# apollo3 register map
Vendor: Ambiq Micro; Series: Apollo; File version: 1.0
CPU: CM4 r1p0, little endian, MPU, FPU, 3 interrupt priority bits
Registers are 32-bit, read-write, reset 0x0 unless marked. A register's access mark holds for its fields unless they carry their own. Offsets are from the block's base; [hi:lo] are bit positions; 'fields as' and 'values as' point back to an identical list.

## MCUCTRL — MCU Miscellaneous Control Logic
Base 0x40020000
0x00 CHIPPN reset 0x4000000 — Chip Information Register
  [31:0] PARTNUM — BCD part number.
    0x6000000=APOLLO3 (Apollo3 part number is 0x06xxxxxx. value.); 0x3000000=APOLLO2 (Apollo2 part number is 0x03xxxxxx. value.); 0x1000000=APOLLO (Apollo part number is 0x01xxxxxx. value.); 0xFF000000=PN_M (Mask for the part number field. value.); 24=PN_S (Bit position for the part number field. value.); 0xF00000=FLASHSIZE_M (Mask for the FLASH_SIZE field. Values: 0: 16KB 1: 32KB 2: 64KB 3: 128KB 4: 256KB 5: 512KB 6: 1MB 7: 2MB value.); 20=FLASHSIZE_S (Bit position for the FLASH_SIZE field. value.); 0xF0000=SRAMSIZE_M (Mask for the SRAM_SIZE field. Values: 0: 16KB 1: 32KB 2: 64KB 3: 128KB 4: 256KB 5: 512KB 6: 1MB 7: 384KB value.); 16=SRAMSIZE_S (Bit position for the SRAM_SIZE field. value.); 0xFF00=REV_M (Mask for the revision field. Bits [15:12] are major rev, [11:8] are minor rev. Values: 0: Major Rev A, Minor Rev 0 1: Major Rev B, Minor Rev 1 value.); 8=REV_S (Bit position for the revision field. value.); 192=PKG_M (Mask for the package field. Values: 0: SIP 1: QFN 2: BGA 3: CSP value.); 6=PKG_S (Bit position for the package field. value.); 56=PINS_M (Mask for the pins field. Values: 0: 25 pins 1: 49 pins 2: 64 pins 3: 81 pins value.); 3=PINS_S (Bit position for the pins field. value.); 1=TEMP_S (Bit position for the temperature field. value.); 0=QUAL_S (Bit position for the qualified field. value.)
0x04 CHIPID0 — Unique Chip ID 0
  [31:0] CHIPID0 — Unique chip ID 0.
    0=APOLLO3 (Apollo3 CHIPID0. value.)
0x08 CHIPID1 — Unique Chip ID 1
  [31:0] CHIPID1 — Unique chip ID 1.
    0=APOLLO3 (Apollo3 CHIPID1. value.)
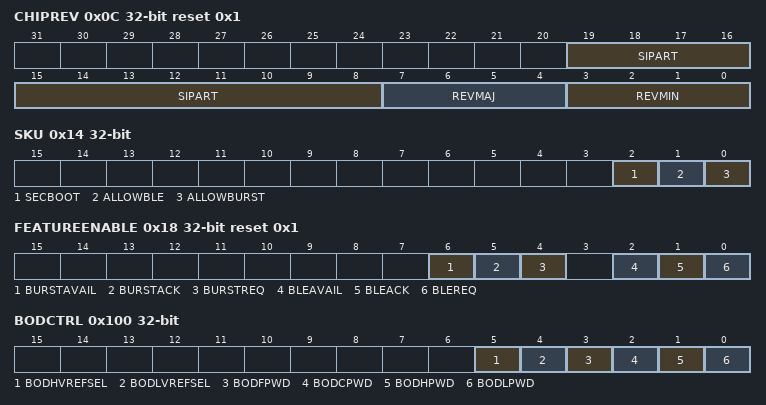
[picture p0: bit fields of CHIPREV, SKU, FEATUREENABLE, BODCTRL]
0x0C CHIPREV reset 0x1 — Chip Revision
  [19:8] SIPART — Silicon Part ID
  [7:4] REVMAJ — Major Revision ID.
    1=A (Apollo3 revision A value.)
  [3:0] REVMIN — Minor Revision ID.
    2=REV1 (Apollo3 minor rev 1. value.); 1=REV0 (Apollo3 minor rev 0. Minor revision value, succeeding minor revisions will increment from this value. value.)
0x10 VENDORID — Unique Vendor ID
  [31:0] VENDORID
    0x414D4251=AMBIQ (Ambiq Vendor ID value.)
0x14 SKU — Unique Chip SKU
  [2] SECBOOT — Secure boot feature allowed
  [1] ALLOWBLE — Allow BLE feature
  [0] ALLOWBURST — Allow Burst feature
0x18 FEATUREENABLE reset 0x1 — Feature Enable on Burst and BLE
  [6] BURSTAVAIL — Availability of Burst functionality
    1=AVAIL (Burst functionality available value.); 0=NOTAVAIL (Burst functionality not available value.)
  [5] BURSTACK — ACK for BURSTREQ
  [4] BURSTREQ — Controls the Burst functionality
    1=EN (Enable the Burst functionality value.); 0=DIS (Disable the Burst functionality value.)
  [2] BLEAVAIL — AVAILABILITY of the BLE functionality
    1=AVAIL (BLE functionality available value.); 0=NOTAVAIL (BLE functionality not available value.)
  [1] BLEACK — ACK for BLEREQ
  [0] BLEREQ — Controls the BLE functionality
    1=EN (Enable the BLE functionality value.); 0=DIS (Disable the BLE functionality value.)
0x20 DEBUGGER — Debugger Control
  [0] LOCKOUT — Lockout of debugger (SWD).
0x100 BODCTRL — BOD control Register
  [5] BODHVREFSEL — BODH External Reference Select. Note: the SWE mux select in PWRSEQ2SWE must be set for this to take effect.
  [4] BODLVREFSEL — BODL External Reference Select. Note: the SWE mux select in PWRSEQ2SWE must be set for this to take effect.
  [3] BODFPWD — BODF Power Down.
  [2] BODCPWD — BODC Power Down.
  [1] BODHPWD — BODH Power Down.
  [0] BODLPWD — BODL Power Down.
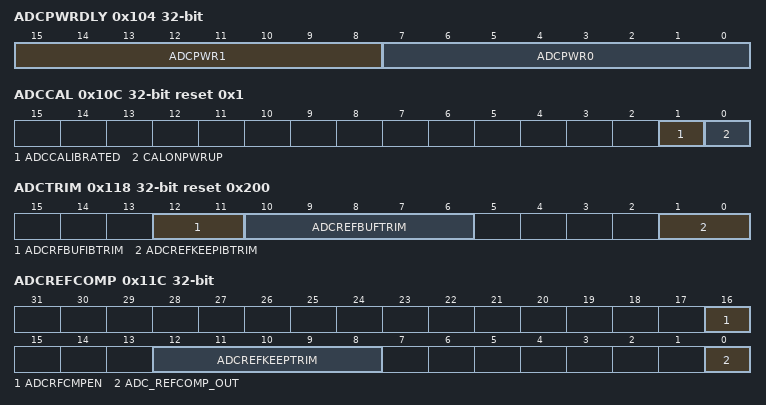
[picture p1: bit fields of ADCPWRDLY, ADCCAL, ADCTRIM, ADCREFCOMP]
0x104 ADCPWRDLY — ADC Power Up Delay Control
  [15:8] ADCPWR1 — ADC Reference Keeper enable delay in 16 ADC CLK increments for ADC_CLKSEL = 0x1, 8 ADC CLOCK increments for ADC_CLKSEL = 0x2.
  [7:0] ADCPWR0 — ADC Reference Buffer Power Enable delay in 64 ADC CLK increments for ADC_CLKSEL = 0x1, 32 ADC CLOCK increments for ADC_CLKSEL = 0x2.
0x10C ADCCAL reset 0x1 — ADC Calibration Control
  [1] ADCCALIBRATED — Status for ADC Calibration
    0=FALSE (ADC is not calibrated value.); 1=TRUE (ADC is calibrated value.)
  [0] CALONPWRUP — Run ADC Calibration on initial power up sequence
    0=DIS (Disable automatic calibration on initial power up value.); 1=EN (Enable automatic calibration on initial power up value.)
0x110 ADCBATTLOAD — ADC Battery Load Enable
  [0] BATTLOAD — Enable the ADC battery load resistor
    0=DIS (Battery load is disconnected value.); 1=EN (Battery load is enabled value.)
0x118 ADCTRIM reset 0x200 — ADC Trims
  [12:11] ADCRFBUFIBTRIM — ADC reference buffer input bias trim
  [10:6] ADCREFBUFTRIM — ADC Reference buffer trim
  [1:0] ADCREFKEEPIBTRIM — ADC Reference Ibias trim
0x11C ADCREFCOMP — ADC Referece Keeper and Comparator Control
  [16] ADCRFCMPEN — ADC Reference comparator power down
  [12:8] ADCREFKEEPTRIM — ADC Reference Keeper Trim
  [0] ADC_REFCOMP_OUT — Output of the ADC reference comparator
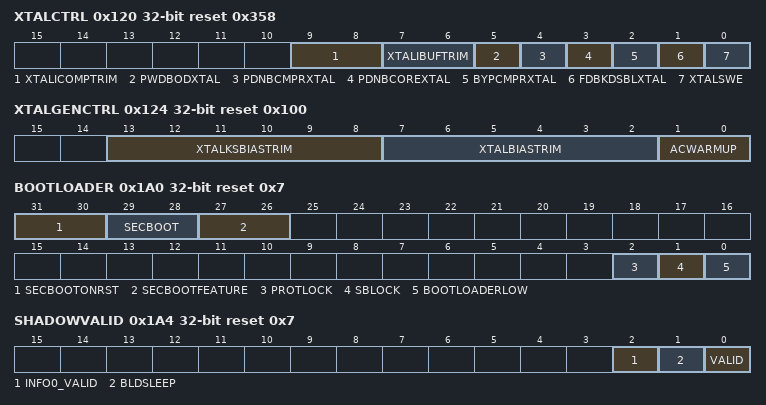
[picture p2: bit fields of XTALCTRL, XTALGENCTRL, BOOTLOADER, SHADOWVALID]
0x120 XTALCTRL reset 0x358 — XTAL Oscillator Control
  [9:8] XTALICOMPTRIM
  [7:6] XTALIBUFTRIM — XTAL IBUFF trim
  [5] PWDBODXTAL — XTAL Power down on brown out.
    0=PWRUPBOD (Power up xtal on BOD value.); 1=PWRDNBOD (Power down XTAL on BOD. value.)
  [4] PDNBCMPRXTAL — XTAL Oscillator Power Down Comparator.
    1=PWRUPCOMP (Power up XTAL oscillator comparator. value.); 0=PWRDNCOMP (Power down XTAL oscillator comparator. value.)
  [3] PDNBCOREXTAL — XTAL Oscillator Power Down Core.
    1=PWRUPCORE (Power up XTAL oscillator core. value.); 0=PWRDNCORE (Power down XTAL oscillator core. value.)
  [2] BYPCMPRXTAL — XTAL Oscillator Bypass Comparator.
    0=USECOMP (Use the XTAL oscillator comparator. value.); 1=BYPCOMP (Bypass the XTAL oscillator comparator. value.)
  [1] FDBKDSBLXTAL — XTAL Oscillator Disable Feedback.
    0=EN (Enable XTAL oscillator comparator. value.); 1=DIS (Disable XTAL oscillator comparator. value.)
  [0] XTALSWE — XTAL Software Override Enable.
    0=OVERRIDE_DIS (XTAL Software Override Disable. value.); 1=OVERRIDE_EN (XTAL Software Override Enable. value.)
0x124 XTALGENCTRL reset 0x100 — XTAL Oscillator General Control
  [13:8] XTALKSBIASTRIM — XTAL IBIAS Kick start trim. This trim value is used during the startup process to enable a faster lock.
  [7:2] XTALBIASTRIM
  [1:0] ACWARMUP — Auto-calibration delay control
    0=SEC1 (Warmup period of 1-2 seconds value.); 1=SEC2 (Warmup period of 2-4 seconds value.); 2=SEC4 (Warmup period of 4-8 seconds value.); 3=SEC8 (Warmup period of 8-16 seconds value.)
0x198 MISCCTRL — Miscellaneous control register.
  [5] BLE_RESETN — BLE reset signal.
0x1A0 BOOTLOADER reset 0x7 — Bootloader and secure boot functions
  [31:30] SECBOOTONRST — Indicates whether the secure boot on warm reset is enabled
    0=DISABLED (Secure boot disabled value.); 1=ENABLED (Secure boot enabled value.); 2=ERROR (Error in secure boot configuration value.)
  [29:28] SECBOOT — Indicates whether the secure boot on cold reset is enabled
    values as SECBOOTONRST
  [27:26] SECBOOTFEATURE — Indicates whether the secure boot feature is enabled.
    values as SECBOOTONRST
  [2] PROTLOCK — Flash protection lock. Always resets to 1, write 1 to clear. Enables writes to flash protection register set.
    1=LOCK (Enable the secure boot lock value.)
  [1] SBLOCK — Secure boot lock. Always resets to 1, write 1 to clear. Enables system visibility to bootloader until set.
    1=LOCK (Enable the secure boot lock value.)
  [0] BOOTLOADERLOW — Determines whether the bootloader code is visible at address 0x00000000 or not. Resets to 1, write 1 to clear.
    1=ADDR0 (Bootloader code at 0x00000000. value.)
0x1A4 SHADOWVALID reset 0x7 — Register to indicate whether the shadow registers have been successfully loaded from the Flash Information Space.
  [2] INFO0_VALID — Indicates whether info0 contains valid data
    1=VALID (Flash info0 (customer) space contains valid data. value.)
  [1] BLDSLEEP — Indicates whether the bootloader should sleep or deep sleep if no image loaded.
    1=DEEPSLEEP (Bootloader will go to deep sleep if no flash image loaded value.)
  [0] VALID — Indicates whether the shadow registers contain valid data from the Flash Information Space.
    1=VALID (Flash information space contains valid data. value.)
0x1B0 SCRATCH0 — Scratch register that is not reset by any reset
  [31:0] SCRATCH0 — Scratch register 0.
0x1B4 SCRATCH1 — Scratch register that is not reset by any reset
  [31:0] SCRATCH1 — Scratch register 1.
0x1C0 ICODEFAULTADDR — ICODE bus address which was present when a bus fault occurred.
  [31:0] ICODEFAULTADDR — The ICODE bus address observed when a Bus Fault occurred. Once an address is captured in this field, it is held until the corresponding Fault Observed bit is cleared in the FAULTSTATUS register.
0x1C4 DCODEFAULTADDR — DCODE bus address which was present when a bus fault occurred.
  [31:0] DCODEFAULTADDR — The DCODE bus address observed when a Bus Fault occurred. Once an address is captured in this field, it is held until the corresponding Fault Observed bit is cleared in the FAULTSTATUS register.
0x1C8 SYSFAULTADDR — System bus address which was present when a bus fault occurred.
  [31:0] SYSFAULTADDR — SYS bus address observed when a Bus Fault occurred. Once an address is captured in this field, it is held until the corresponding Fault Observed bit is cleared in the FAULTSTATUS register.
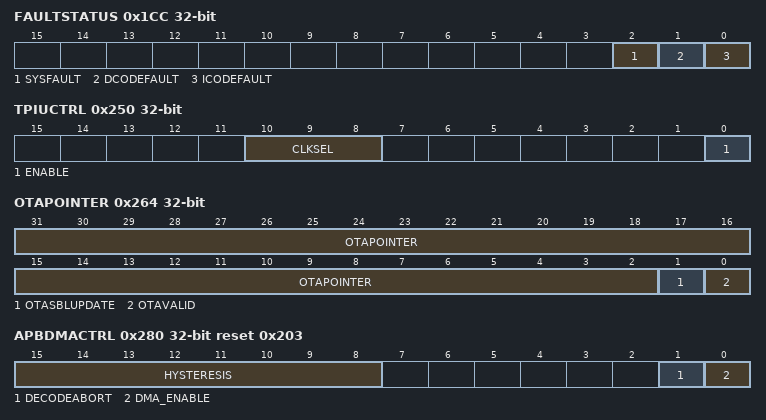
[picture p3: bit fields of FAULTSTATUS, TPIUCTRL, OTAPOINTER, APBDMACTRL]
0x1CC FAULTSTATUS — Reflects the status of the bus decoders' fault detection. Any write to this register will clear all of the status bits within the register.
  [2] SYSFAULT — SYS Bus Decoder Fault Detected bit. When set, a fault has been detected, and the SYSFAULTADDR register will contain the bus address which generated the fault.
    0=NOFAULT (No bus fault has been detected. value.); 1=FAULT (Bus fault detected. value.)
  [1] DCODEFAULT — DCODE Bus Decoder Fault Detected bit. When set, a fault has been detected, and the DCODEFAULTADDR register will contain the bus address which generated the fault.
    0=NOFAULT (No DCODE fault has been detected. value.); 1=FAULT (DCODE fault detected. value.)
  [0] ICODEFAULT — The ICODE Bus Decoder Fault Detected bit. When set, a fault has been detected, and the ICODEFAULTADDR register will contain the bus address which generated the fault.
    0=NOFAULT (No ICODE fault has been detected. value.); 1=FAULT (ICODE fault detected. value.)
0x1D0 FAULTCAPTUREEN — Enable the fault capture registers
  [0] FAULTCAPTUREEN — Fault Capture Enable field. When set, the Fault Capture monitors are enabled and addresses which generate a hard fault are captured into the FAULTADDR registers.
    0=DIS (Disable fault capture. value.); 1=EN (Enable fault capture. value.)
0x200 DBGR1 reset 0x12345678 — Read-only debug register 1
  [31:0] ONETO8 — Read-only register for communication validation
0x204 DBGR2 reset 0xC001C0DE — Read-only debug register 2
  [31:0] COOLCODE — Read-only register for communication validation
0x220 PMUENABLE reset 0x1 — Control bit to enable/disable the PMU
  [0] ENABLE — PMU Enable Control bit. When set, the MCU's PMU will place the MCU into the lowest power consuming Deep Sleep mode upon execution of a WFI instruction (dependent on the setting of the SLEEPDEEP bit in the ARM SCR register). When cleared, regardless of the requested sleep mode, the PMU will not enter the lowest power Deep Sleep mode, instead entering the Sleep mode.
    0=DIS (Disable MCU power management. value.); 1=EN (Enable MCU power management. value.)
0x250 TPIUCTRL — TPIU Control Register. Determines the clock enable and frequency for the M4's TPIU interface.
  [10:8] CLKSEL — This field selects the frequency of the ARM M4 TPIU port.
    0=LOWPWR (Low power state. value.); 1=HFRCDIV2 (Selects HFRC divided by 2 as the source TPIU clk value.); 2=HFRCDIV8 (Selects HFRC divided by 8 as the source TPIU clk value.); 3=HFRCDIV16 (Selects HFRC divided by 16 as the source TPIU clk value.); 4=HFRCDIV32 (Selects HFRC divided by 32 as the source TPIU clk value.)
  [0] ENABLE — TPIU Enable field. When set, the ARM M4 TPIU is enabled and data can be streamed out of the MCU's SWO port using the ARM ITM and TPIU modules.
    0=DIS (Disable the TPIU. value.); 1=EN (Enable the TPIU. value.)
0x264 OTAPOINTER — OTA (Over the Air) Update Pointer/Status. Reset only by POA
  [31:2] OTAPOINTER — Flash page pointer with updated OTA image
  [1] OTASBLUPDATE — Indicates that the sbl_init has been updated
  [0] OTAVALID — Indicates that an OTA update is valid
0x280 APBDMACTRL reset 0x203 — DMA Control Register. Determines misc settings for DMA operation
  [15:8] HYSTERESIS — This field determines how long the DMA will remain active during deep sleep before shutting down and returning the system to full deep sleep. Values are based on a 94KHz clock and are roughly 10us increments for a range of ~10us to 2.55ms
  [1] DECODEABORT — APB Decode Abort. When set, the APB bridge will issue a data abort (bus fault) on transactions to peripherals that are powered down. When set to 0, writes are quietly discarded and reads return 0.
    0=DISABLE (Bus operations to powered down peripherals are quietly discarded value.); 1=ENABLE (Bus operations to powered down peripherals result in a bus fault. value.)
  [0] DMA_ENABLE — Enable the DMA controller. When disabled, DMA requests will be ignored by the controller
    0=DISABLE (DMA operations disabled value.); 1=ENABLE (DMA operations enabled value.)
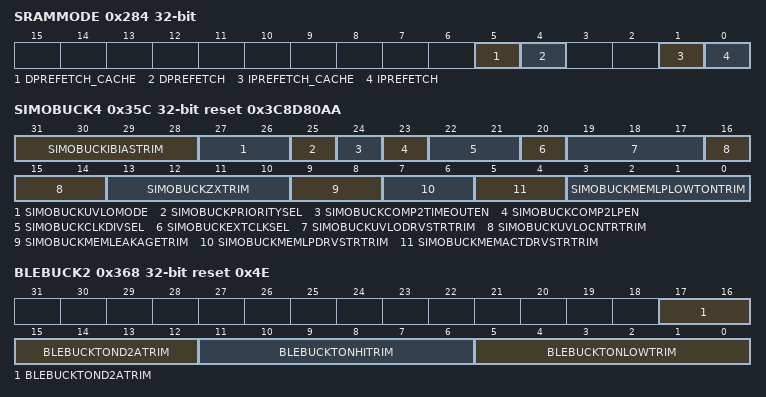
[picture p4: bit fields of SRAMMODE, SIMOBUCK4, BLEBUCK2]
0x284 SRAMMODE — SRAM Controller mode bits
  [5] DPREFETCH_CACHE — Secondary prefetch feature that will cache prefetched data across bus waitstates (requires DPREFETCH to be set).
  [4] DPREFETCH — When set, data bus accesses to the SRAM banks will be prefetched (normally 2 cycle read access). Use of this mode bit is only recommended if the work flow has a large number of sequential accesses.
  [1] IPREFETCH_CACHE — Secondary prefetch feature that will cache prefetched data across bus waitstates (requires IPREFETCH to be set).
  [0] IPREFETCH — When set, instruction accesses to the SRAM banks will be prefetched (normally 2 cycle read access). Generally, this mode bit should be set for improved performance when executing instructions from SRAM.
0x348 KEXTCLKSEL — Key Register to enable the use of external clock selects via the EXTCLKSEL reg
  [31:0] KEXTCLKSEL — Key register value.
    83=Key (Key value.)
0x35C SIMOBUCK4 reset 0x3C8D80AA — SIMO Buck Control Reg1
  [31:28] SIMOBUCKIBIASTRIM — simobuck_bias_trim
  [27:26] SIMOBUCKUVLOMODE
  [25] SIMOBUCKPRIORITYSEL
  [24] SIMOBUCKCOMP2TIMEOUTEN
  [23] SIMOBUCKCOMP2LPEN
  [22:21] SIMOBUCKCLKDIVSEL
  [20] SIMOBUCKEXTCLKSEL
  [19:17] SIMOBUCKUVLODRVSTRTRIM
  [16:14] SIMOBUCKUVLOCNTRTRIM
  [13:10] SIMOBUCKZXTRIM
  [9:8] SIMOBUCKMEMLEAKAGETRIM
  [7:6] SIMOBUCKMEMLPDRVSTRTRIM
  [5:4] SIMOBUCKMEMACTDRVSTRTRIM
  [3:0] SIMOBUCKMEMLPLOWTONTRIM
0x368 BLEBUCK2 reset 0x4E — BLEBUCK2 Control Reg
  [17:12] BLEBUCKTOND2ATRIM — blebuck_ton_trim
  [11:6] BLEBUCKTONHITRIM
  [5:0] BLEBUCKTONLOWTRIM
0x3A0 FLASHWPROT0 — Flash Write Protection Bits
  [31:0] FW0BITS — Write protect flash 0x00000000 - 0x0007FFFF. Each bit provides write protection for 16KB chunks of flash data space. Bits are cleared by writing a 1 to the bit. When read, 0 indicates the region is protected. Bits are sticky (can be set when PROTLOCK is 1, but only cleared by reset)
0x3A4 FLASHWPROT1 — Flash Write Protection Bits
  [31:0] FW1BITS — Write protect flash 0x00080000 - 0x000FFFFF. Each bit provides write protection for 16KB chunks of flash data space. Bits are cleared by writing a 1 to the bit. When read, 0 indicates the region is protected. Bits are sticky (can be set when PROTLOCK is 1, but only cleared by reset)
0x3B0 FLASHRPROT0 — Flash Read Protection Bits
  [31:0] FR0BITS — Copy (read) protect flash 0x00000000 - 0x0007FFFF. Each bit provides read protection for 16KB chunks of flash. Bits are cleared by writing a 1 to the bit. When read, 0 indicates the region is protected. Bits are sticky (can be set when PROTLOCK is 1, but only cleared by reset)
0x3B4 FLASHRPROT1 — Flash Read Protection Bits
  [31:0] FR1BITS — Copy (read) protect flash 0x00080000 - 0x000FFFFF. Each bit provides read protection for 16KB chunks of flash. Bits are cleared by writing a 1 to the bit. When read, 0 indicates the region is protected. Bits are sticky (can be set when PROTLOCK is 1, but only cleared by reset)
0x3C0 DMASRAMWRITEPROTECT0 — SRAM write-protection bits.
  [31:0] DMA_WPROT0 — Write protect SRAM from DMA. Each bit provides write protection for an 8KB region of memory. When set to 1, the region will be protected from DMA writes, when set to 0, DMA may write the region.
0x3C4 DMASRAMWRITEPROTECT1 — SRAM write-protection bits.
  [15:0] DMA_WPROT1 — Write protect SRAM from DMA. Each bit provides write protection for an 8KB region of memory. When set to 1, the region will be protected from DMA writes, when set to 0, DMA may write the region.
0x3D0 DMASRAMREADPROTECT0 — SRAM read-protection bits.
  [31:0] DMA_RPROT0 — Read protect SRAM from DMA. Each bit provides write protection for an 8KB region of memory. When set to 1, the region will be protected from DMA reads, when set to 0, DMA may read the region.
0x3D4 DMASRAMREADPROTECT1 — SRAM read-protection bits.
  [15:0] DMA_RPROT1 — Read protect SRAM from DMA. Each bit provides write protection for an 8KB region of memory. When set to 1, the region will be protected from DMA reads, when set to 0, DMA may read the region.
